VERSION "MUR_SBG_Ellipse_v1.0"

NS_ :

BS_:

BU_: SBG ECU TELEMETRY

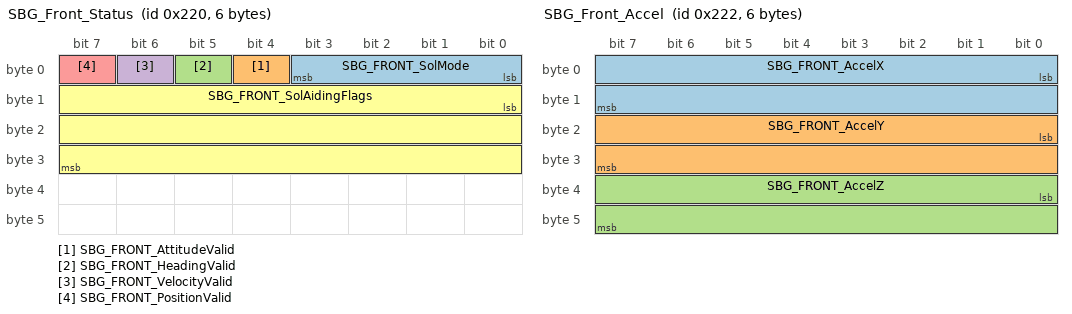
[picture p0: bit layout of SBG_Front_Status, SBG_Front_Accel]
BO_ 544 SBG_Front_Status: 6 SBG
 SG_ SBG_FRONT_SolMode : 0|4@1+ (1,0) [0|15] "" ECU,TELEMETRY
 SG_ SBG_FRONT_AttitudeValid : 4|1@1+ (1,0) [0|1] "" ECU,TELEMETRY
 SG_ SBG_FRONT_HeadingValid : 5|1@1+ (1,0) [0|1] "" ECU,TELEMETRY
 SG_ SBG_FRONT_VelocityValid : 6|1@1+ (1,0) [0|1] "" ECU,TELEMETRY
 SG_ SBG_FRONT_PositionValid : 7|1@1+ (1,0) [0|1] "" ECU,TELEMETRY
 SG_ SBG_FRONT_SolAidingFlags : 8|24@1+ (1,0) [0|16777215] "" ECU,TELEMETRY

BO_ 545 SBG_Front_Utc: 8 SBG
 SG_ SBG_FRONT_TimeStamp : 0|32@1+ (1,0) [0|4294967295] "us" ECU,TELEMETRY
 SG_ SBG_FRONT_GpsTow : 32|32@1+ (1,0) [0|4294967295] "ms" ECU,TELEMETRY

BO_ 546 SBG_Front_Accel: 6 SBG
 SG_ SBG_FRONT_AccelX : 0|16@1- (0.01,0) [-327.68|327.67] "m/s^2" ECU,TELEMETRY
 SG_ SBG_FRONT_AccelY : 16|16@1- (0.01,0) [-327.68|327.67] "m/s^2" ECU,TELEMETRY
 SG_ SBG_FRONT_AccelZ : 32|16@1- (0.01,0) [-327.68|327.67] "m/s^2" ECU,TELEMETRY

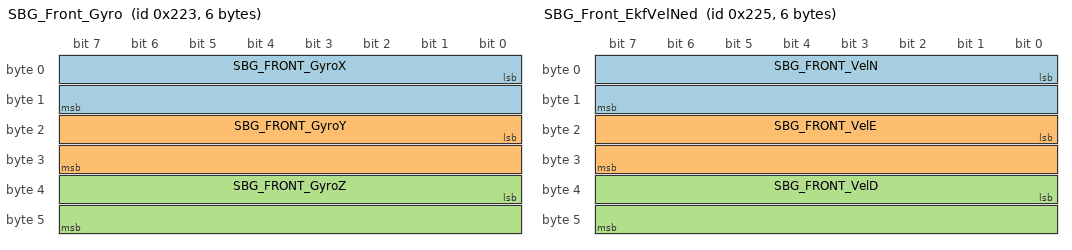
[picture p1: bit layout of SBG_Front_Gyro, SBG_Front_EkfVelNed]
BO_ 547 SBG_Front_Gyro: 6 SBG
 SG_ SBG_FRONT_GyroX : 0|16@1- (0.001,0) [-32.768|32.767] "rad/s" ECU,TELEMETRY
 SG_ SBG_FRONT_GyroY : 16|16@1- (0.001,0) [-32.768|32.767] "rad/s" ECU,TELEMETRY
 SG_ SBG_FRONT_GyroZ : 32|16@1- (0.001,0) [-32.768|32.767] "rad/s" ECU,TELEMETRY

BO_ 548 SBG_Front_EkfPos: 8 SBG
 SG_ SBG_FRONT_Latitude : 0|32@1- (1E-007,0) [-90|90] "deg" ECU,TELEMETRY
 SG_ SBG_FRONT_Longitude : 32|32@1- (1E-007,0) [-180|180] "deg" ECU,TELEMETRY

BO_ 549 SBG_Front_EkfVelNed: 6 SBG
 SG_ SBG_FRONT_VelN : 0|16@1- (0.01,0) [-327.68|327.67] "m/s" ECU,TELEMETRY
 SG_ SBG_FRONT_VelE : 16|16@1- (0.01,0) [-327.68|327.67] "m/s" ECU,TELEMETRY
 SG_ SBG_FRONT_VelD : 32|16@1- (0.01,0) [-327.68|327.67] "m/s" ECU,TELEMETRY

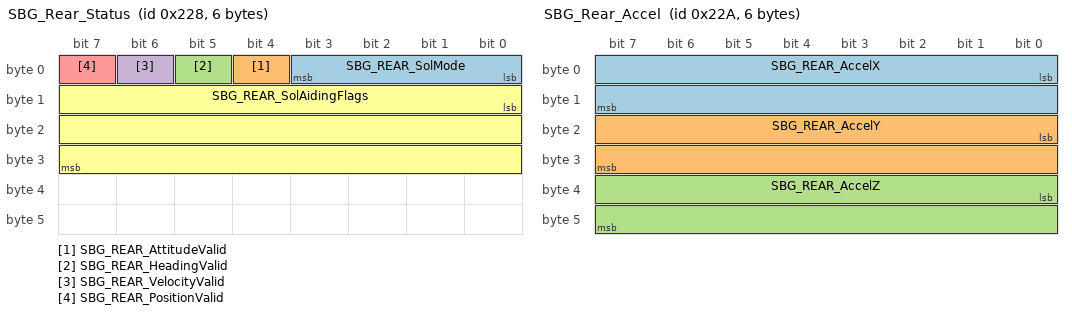
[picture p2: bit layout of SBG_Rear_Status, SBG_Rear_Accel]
BO_ 552 SBG_Rear_Status: 6 SBG
 SG_ SBG_REAR_SolMode : 0|4@1+ (1,0) [0|15] "" ECU,TELEMETRY
 SG_ SBG_REAR_AttitudeValid : 4|1@1+ (1,0) [0|1] "" ECU,TELEMETRY
 SG_ SBG_REAR_HeadingValid : 5|1@1+ (1,0) [0|1] "" ECU,TELEMETRY
 SG_ SBG_REAR_VelocityValid : 6|1@1+ (1,0) [0|1] "" ECU,TELEMETRY
 SG_ SBG_REAR_PositionValid : 7|1@1+ (1,0) [0|1] "" ECU,TELEMETRY
 SG_ SBG_REAR_SolAidingFlags : 8|24@1+ (1,0) [0|16777215] "" ECU,TELEMETRY

BO_ 553 SBG_Rear_Utc: 8 SBG
 SG_ SBG_REAR_TimeStamp : 0|32@1+ (1,0) [0|4294967295] "us" ECU,TELEMETRY
 SG_ SBG_REAR_GpsTow : 32|32@1+ (1,0) [0|4294967295] "ms" ECU,TELEMETRY

BO_ 554 SBG_Rear_Accel: 6 SBG
 SG_ SBG_REAR_AccelX : 0|16@1- (0.01,0) [-327.68|327.67] "m/s^2" ECU,TELEMETRY
 SG_ SBG_REAR_AccelY : 16|16@1- (0.01,0) [-327.68|327.67] "m/s^2" ECU,TELEMETRY
 SG_ SBG_REAR_AccelZ : 32|16@1- (0.01,0) [-327.68|327.67] "m/s^2" ECU,TELEMETRY

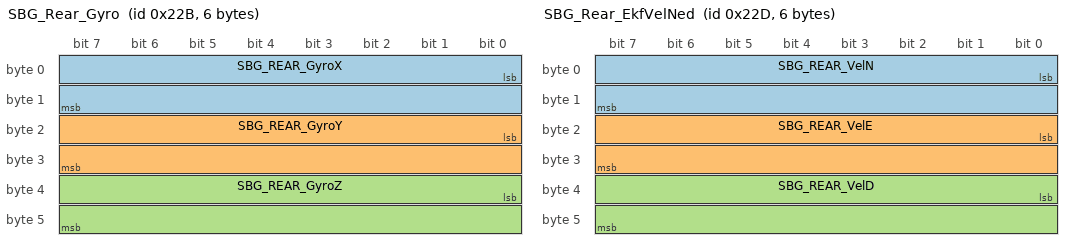
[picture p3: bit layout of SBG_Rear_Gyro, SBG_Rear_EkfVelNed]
BO_ 555 SBG_Rear_Gyro: 6 SBG
 SG_ SBG_REAR_GyroX : 0|16@1- (0.001,0) [-32.768|32.767] "rad/s" ECU,TELEMETRY
 SG_ SBG_REAR_GyroY : 16|16@1- (0.001,0) [-32.768|32.767] "rad/s" ECU,TELEMETRY
 SG_ SBG_REAR_GyroZ : 32|16@1- (0.001,0) [-32.768|32.767] "rad/s" ECU,TELEMETRY

BO_ 556 SBG_Rear_EkfPos: 8 SBG
 SG_ SBG_REAR_Latitude : 0|32@1- (1E-007,0) [-90|90] "deg" ECU,TELEMETRY
 SG_ SBG_REAR_Longitude : 32|32@1- (1E-007,0) [-180|180] "deg" ECU,TELEMETRY

BO_ 557 SBG_Rear_EkfVelNed: 6 SBG
 SG_ SBG_REAR_VelN : 0|16@1- (0.01,0) [-327.68|327.67] "m/s" ECU,TELEMETRY
 SG_ SBG_REAR_VelE : 16|16@1- (0.01,0) [-327.68|327.67] "m/s" ECU,TELEMETRY
 SG_ SBG_REAR_VelD : 32|16@1- (0.01,0) [-327.68|327.67] "m/s" ECU,TELEMETRY

CM_ BU_ SBG "2x SBG Ellipse-D (ELLIPSE-D-G4A3-B2, P/N 100-2425: Land Air INS, dual-antenna GNSS RTK, CAN) on Telemetry CAN, front + rear. Frame layouts, scaling and signedness are copied from SBG's official sbgCan.dbc (github.com/SBG-Systems/sbgECom, can/sbgCan.dbc) and checked against its doc/canProtocol.md; payloads are little-endian. Only the IDs are MUR's: SBG ships every CAN message disabled, and both units are remapped into the 0x220-0x22F block mur_telemetry_can.dbc reserves - front 0x220-0x225 (0x226-0x227 spare), rear 0x228-0x22D (0x22E-0x22F spare). The relative order follows SBG's default IDs. This file is only true while the units are configured to match (sbgCenter: Input/Output > CAN bus Normal @ 1000 kbit/s + IDs; Data Output > the six messages below at their GenMsgCycleTime rates, everything else off). Position/velocity are the Navigation (EKF) outputs, not GNSS1. MUR ADDITION (PROVISIONAL): ID plan pending telemetry team sign-off.";
CM_ BO_ 544 "SBG_ECAN_MSG_STATUS_03 (SBG default ID 0x102), front unit. Bytes 4-5 are HEAVE_STATUS (ship-motion status, meaningless on a car) - left undefined.";
CM_ SG_ 544 SBG_FRONT_SolMode "SOLUTION_STATUS bits 0-3: EKF solution mode. Nothing but NavPosition means position/velocity are trustworthy.";
CM_ SG_ 544 SBG_FRONT_SolAidingFlags "SOLUTION_STATUS bits 8-31: aiding-used flags, SBG_ECOM_SOL_* bit N maps to bit N-8 here (e.g. bit 11 GPS1_POS_USED -> bit 3, bit 27 ALIGN_VALID -> bit 19). See sbgECom doc/binaryMessages.md SOLUTION_STATUS.";
CM_ BO_ 545 "SBG_ECAN_MSG_UTC_0 (SBG default ID 0x110), front unit. TimeStamp is time since the unit powered up; GpsTow is GPS time of week - use it to line up the two units and other logs.";
CM_ BO_ 546 "SBG_ECAN_MSG_IMU_ACCEL (SBG default ID 0x121), front unit. Calibrated accelerometer, sensor body frame.";
CM_ BO_ 547 "SBG_ECAN_MSG_IMU_GYRO (SBG default ID 0x122), front unit. Calibrated gyro, sensor body frame.";
CM_ BO_ 548 "SBG_ECAN_MSG_EKF_POS (SBG default ID 0x134), front unit. WGS84 latitude/longitude from the INS solution; invalid until SolMode = NavPosition.";
CM_ BO_ 549 "SBG_ECAN_MSG_EKF_VEL_NED (SBG default ID 0x137), front unit. INS velocity in the North/East/Down frame, not the car frame.";
CM_ BO_ 552 "SBG_ECAN_MSG_STATUS_03 (SBG default ID 0x102), rear unit - same layout as SBG_Front_Status.";
CM_ BO_ 553 "SBG_ECAN_MSG_UTC_0 (SBG default ID 0x110), rear unit - same layout as SBG_Front_Utc.";
CM_ BO_ 554 "SBG_ECAN_MSG_IMU_ACCEL (SBG default ID 0x121), rear unit - same layout as SBG_Front_Accel.";
CM_ BO_ 555 "SBG_ECAN_MSG_IMU_GYRO (SBG default ID 0x122), rear unit - same layout as SBG_Front_Gyro.";
CM_ BO_ 556 "SBG_ECAN_MSG_EKF_POS (SBG default ID 0x134), rear unit - same layout as SBG_Front_EkfPos.";
CM_ BO_ 557 "SBG_ECAN_MSG_EKF_VEL_NED (SBG default ID 0x137), rear unit - same layout as SBG_Front_EkfVelNed.";

BA_DEF_ BO_ "GenMsgCycleTime" INT 0 100000;
BA_DEF_ BO_ "GenMsgSendType" ENUM "Cyclic","OnChange","Event";
BA_DEF_ "BusType" STRING ;
BA_DEF_DEF_ "GenMsgCycleTime" 0;
BA_DEF_DEF_ "GenMsgSendType" "Cyclic";
BA_DEF_DEF_ "BusType" "CAN";
BA_ "GenMsgCycleTime" BO_ 544 100;
BA_ "GenMsgCycleTime" BO_ 545 1000;
BA_ "GenMsgCycleTime" BO_ 546 10;
BA_ "GenMsgCycleTime" BO_ 547 10;
BA_ "GenMsgCycleTime" BO_ 548 100;
BA_ "GenMsgCycleTime" BO_ 549 20;
BA_ "GenMsgCycleTime" BO_ 552 100;
BA_ "GenMsgCycleTime" BO_ 553 1000;
BA_ "GenMsgCycleTime" BO_ 554 10;
BA_ "GenMsgCycleTime" BO_ 555 10;
BA_ "GenMsgCycleTime" BO_ 556 100;
BA_ "GenMsgCycleTime" BO_ 557 20;

VAL_ 544 SBG_FRONT_SolMode 0 "Uninitialized" 1 "VerticalGyro" 2 "AHRS" 3 "NavVelocityDeprecated" 4 "NavPosition" ;
VAL_ 552 SBG_REAR_SolMode 0 "Uninitialized" 1 "VerticalGyro" 2 "AHRS" 3 "NavVelocityDeprecated" 4 "NavPosition" ;
